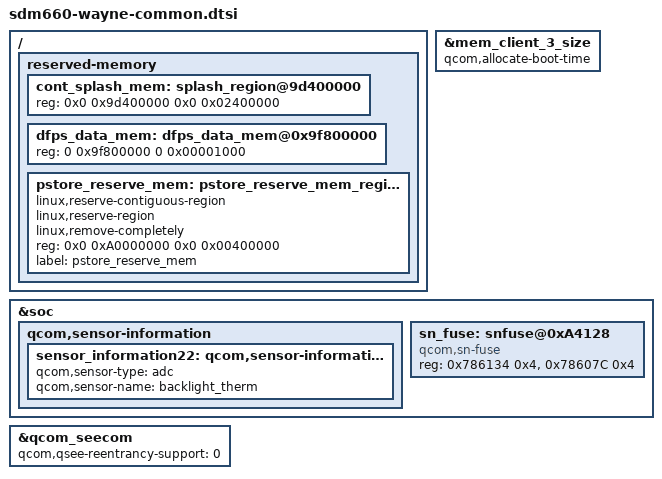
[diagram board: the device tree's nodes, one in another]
/ {
	reserved-memory {
		cont_splash_mem: splash_region@9d400000 {
			reg = <0x0 0x9d400000 0x0 0x02400000>;
		};

		/delete-node/ dfps_data_mem@0x9f7ff000;

		dfps_data_mem: dfps_data_mem@0x9f800000 {
			reg = <0 0x9f800000 0 0x00001000>;
		};

		pstore_reserve_mem: pstore_reserve_mem_region@0 {
			linux,reserve-contiguous-region;
			linux,reserve-region;
			linux,remove-completely;
			reg = <0x0 0xA0000000 0x0 0x00400000>;
			label = "pstore_reserve_mem";
		};
	};
};

&mem_client_3_size {
	/delete-property/ qcom,allocate-on-request;
	qcom,allocate-boot-time;
};

&soc {
	/delete-node/ qcom,qbt1000;

	qcom,sensor-information {
		sensor_information22: qcom,sensor-information-22 {
			qcom,sensor-type = "adc";
			qcom,sensor-name = "backlight_therm";
		};
	};

	sn_fuse: snfuse@0xA4128 {
	compatible = "qcom,sn-fuse";
	reg = <0x786134 0x4>,
		<0x78607C 0x4>;
	reg-names = "sn-base","fuse-state";
	};
};

&qcom_seecom {
	qcom,qsee-reentrancy-support = <0>;
};
